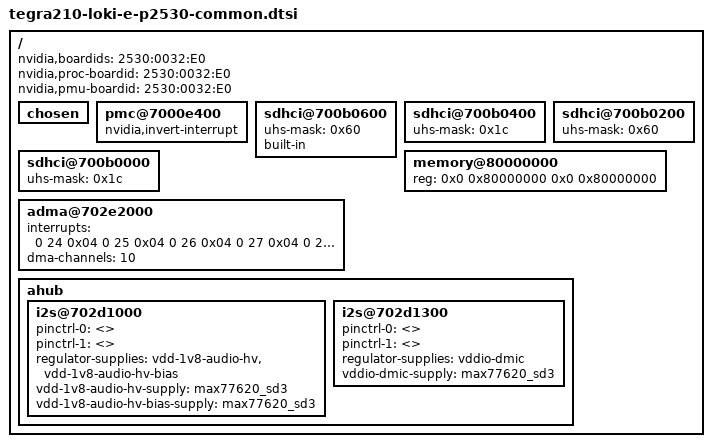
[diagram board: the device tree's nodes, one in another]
/*
 * arch/arm64/boot/dts/tegra210-loki-e-p2530-0032-e00-00.dts
 *
 * Copyright (c) 2014, NVIDIA CORPORATION.  All rights reserved.
 *
 * This program is free software; you can redistribute it and/or modify
 * it under the terms of the GNU General Public License as published by
 * the Free Software Foundation; version 2 of the License.
 *
 * This program is distributed in the hope that it will be useful, but WITHOUT
 * ANY WARRANTY; without even the implied warranty of MERCHANTABILITY or
 * FITNESS FOR A PARTICULAR PURPOSE.  See the GNU General Public License for
 * more details.
 *
 * You should have received a copy of the GNU General Public License along
 * with this program; if not, write to the Free Software Foundation, Inc.,
 * 51 Franklin Street, Fifth Floor, Boston, MA  02110-1301, USA.
 *
 */

/ {
	nvidia,boardids = "2530:0032:E0";
	nvidia,proc-boardid = "2530:0032:E0";
	nvidia,pmu-boardid = "2530:0032:E0";
	#address-cells = <2>;
	#size-cells = <2>;

	chosen {
        };

	pmc@7000e400 {
		nvidia,invert-interrupt;
	};

	sdhci@700b0600 {
		uhs-mask = <0x60>;
		built-in;
		status = "okay";
	};

	sdhci@700b0400 {
		uhs-mask = <0x1c>;
		status = "okay";
	};

	sdhci@700b0200 {
		uhs-mask = <0x60>;
		status = "okay";
	};

	sdhci@700b0000 {
		uhs-mask = <0x1c>;
		status = "okay";
	};

	memory@80000000 {
		device_type = "memory";
		reg = < 0x0 0x80000000 0x0 0x80000000 >;
	};

	adma@702e2000  {
		interrupts = <0 24 0x04
			      0 25 0x04
			      0 26 0x04
			      0 27 0x04
			      0 28 0x04
			      0 29 0x04
			      0 30 0x04
			      0 31 0x04
			      0 32 0x04
			      0 33 0x04>;
		dma-channels = <10>;
		status = "okay";
	};


	ahub {
		i2s@702d1000 {
			pinctrl-names = "dap_active", "dap_inactive";
			pinctrl-0 = <>;
			pinctrl-1 = <>;
			regulator-supplies = "vdd-1v8-audio-hv", "vdd-1v8-audio-hv-bias";
			vdd-1v8-audio-hv-supply = <&max77620_sd3>;
			vdd-1v8-audio-hv-bias-supply = <&max77620_sd3>;
		};

		i2s@702d1300 {
			pinctrl-names = "dap_active", "dap_inactive";
			pinctrl-0 = <>;
			pinctrl-1 = <>;
			regulator-supplies = "vddio-dmic";
			vddio-dmic-supply = <&max77620_sd3>;
		};
	};
};

